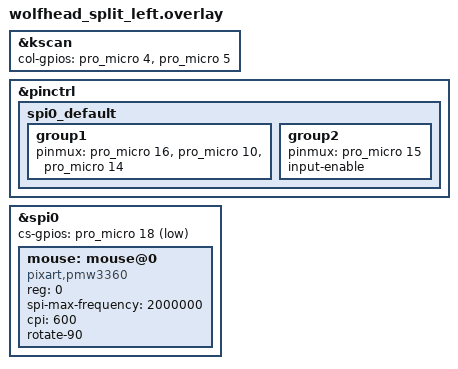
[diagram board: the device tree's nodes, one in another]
// This file was generated from a template. Edit it to match your keyboard.
// See https://zmk.dev/docs/development/hardware-integration/new-shield for more
// instructions.

#include "wolfhead_split.dtsi"

&kscan {
    // Replace these comments with the GPIO pins in the matrix for the left side.
    // See https://zmk.dev/docs/development/hardware-integration/new-shield#shield-overlays
    col-gpios
        = <&pro_micro 4 GPIO_ACTIVE_HIGH>
        , <&pro_micro 5 GPIO_ACTIVE_HIGH>
        ;
};

&pinctrl {
	spi0_default: spi0_default {
		group1 {
			pinmux = <&pro_micro 16>, <&pro_micro 10>, <&pro_micro 14>;
		};
		group2 {
			pinmux = <&pro_micro 15>;
			input-enable;
		};
	};
};

&spi0 {
	status = "okay";
	cs-gpios = <&pro_micro 18 GPIO_ACTIVE_LOW>;
	mouse: mouse@0 {
		compatible = "pixart,pmw3360";
		status = "okay";
		reg = <0>;
		spi-max-frequency = <2000000>;

		// pmw3360 driver parameters
		cpi = <600>;
		rotate-90;
	};
};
